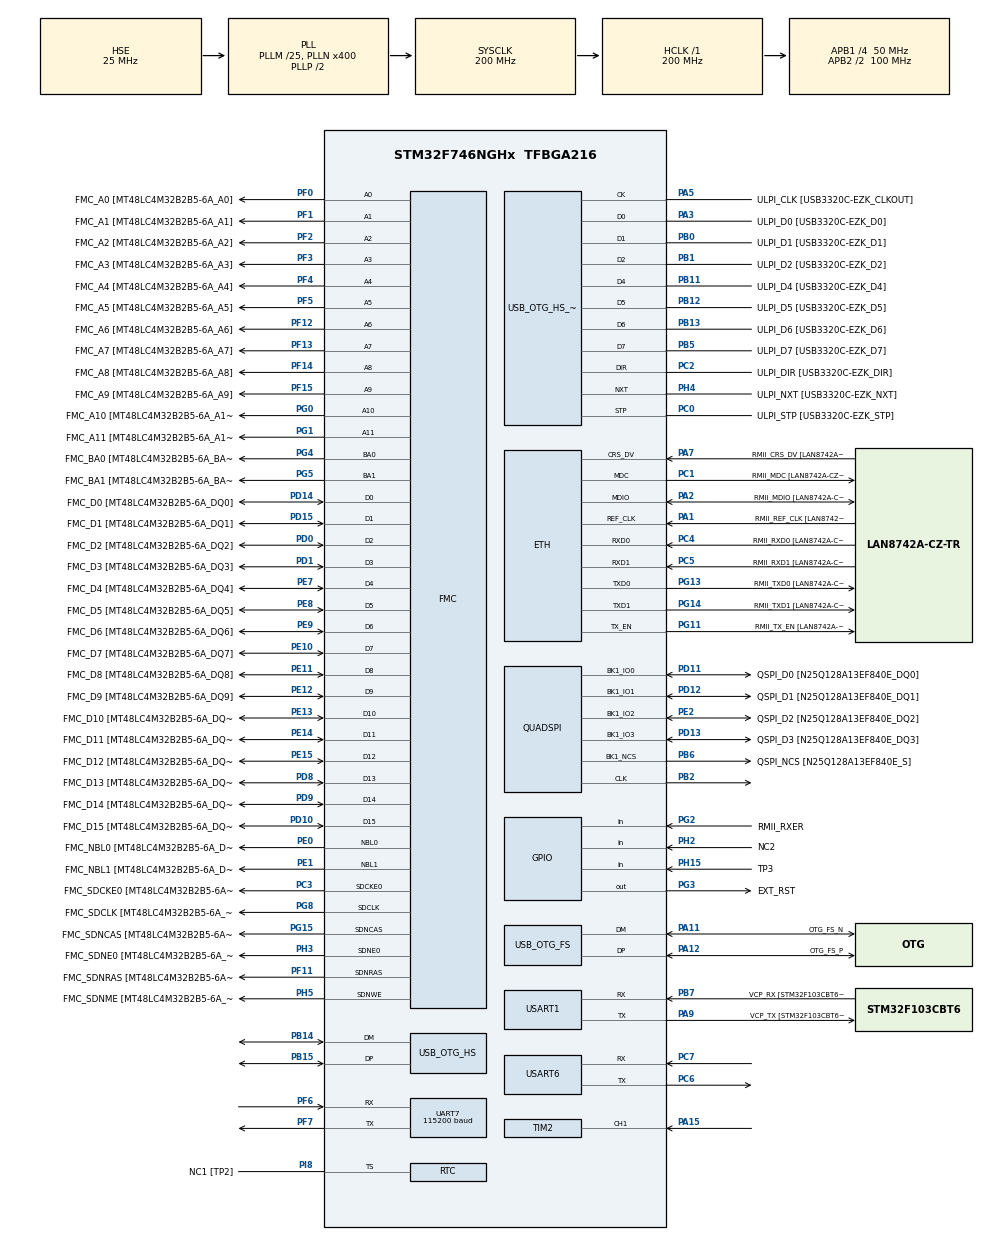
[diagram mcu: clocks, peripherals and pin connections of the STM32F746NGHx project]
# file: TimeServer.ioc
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CORTEX_M7.CPU_DCache=Disabled
CORTEX_M7.CPU_ICache=Disabled
CORTEX_M7.PREFETCH_ENABLE=0
Dma.Request0=USART6_TX
Dma.Request1=UART7_TX
Dma.Request2=USART1_RX
Dma.Request3=USART1_TX
Dma.Request4=USART6_RX
Dma.Request5=UART7_RX
Dma.UART7_RX.5.Direction=DMA_PERIPH_TO_MEMORY
Dma.UART7_RX.5.FIFOMode=DMA_FIFOMODE_ENABLE
Dma.UART7_RX.5.FIFOThreshold=DMA_FIFO_THRESHOLD_FULL
Dma.UART7_RX.5.Instance=DMA1_Stream3
Dma.UART7_RX.5.MemBurst=DMA_MBURST_SINGLE
Dma.UART7_RX.5.MemDataAlignment=DMA_MDATAALIGN_BYTE
Dma.UART7_RX.5.MemInc=DMA_MINC_ENABLE
Dma.UART7_RX.5.Mode=DMA_NORMAL
Dma.UART7_RX.5.PeriphBurst=DMA_PBURST_SINGLE
Dma.UART7_RX.5.PeriphDataAlignment=DMA_PDATAALIGN_BYTE
Dma.UART7_RX.5.PeriphInc=DMA_PINC_DISABLE
Dma.UART7_RX.5.Priority=DMA_PRIORITY_LOW
Dma.UART7_TX.1.Direction=DMA_MEMORY_TO_PERIPH
Dma.UART7_TX.1.FIFOMode=DMA_FIFOMODE_ENABLE
Dma.UART7_TX.1.FIFOThreshold=DMA_FIFO_THRESHOLD_FULL
Dma.UART7_TX.1.Instance=DMA1_Stream1
Dma.UART7_TX.1.MemBurst=DMA_MBURST_SINGLE
Dma.UART7_TX.1.MemDataAlignment=DMA_MDATAALIGN_BYTE
Dma.UART7_TX.1.MemInc=DMA_MINC_ENABLE
Dma.UART7_TX.1.Mode=DMA_NORMAL
Dma.UART7_TX.1.PeriphBurst=DMA_PBURST_SINGLE
Dma.UART7_TX.1.PeriphDataAlignment=DMA_PDATAALIGN_BYTE
Dma.UART7_TX.1.PeriphInc=DMA_PINC_DISABLE
Dma.UART7_TX.1.Priority=DMA_PRIORITY_LOW
Dma.USART1_RX.2.Direction=DMA_PERIPH_TO_MEMORY
Dma.USART1_RX.2.FIFOMode=DMA_FIFOMODE_DISABLE
Dma.USART1_RX.2.Instance=DMA2_Stream2
Dma.USART1_RX.2.MemDataAlignment=DMA_MDATAALIGN_BYTE
Dma.USART1_RX.2.MemInc=DMA_MINC_ENABLE
Dma.USART1_RX.2.Mode=DMA_NORMAL
Dma.USART1_RX.2.PeriphDataAlignment=DMA_PDATAALIGN_BYTE
Dma.USART1_RX.2.PeriphInc=DMA_PINC_DISABLE
Dma.USART1_RX.2.Priority=DMA_PRIORITY_LOW
Dma.USART1_TX.3.Direction=DMA_MEMORY_TO_PERIPH
Dma.USART1_TX.3.FIFOMode=DMA_FIFOMODE_DISABLE
Dma.USART1_TX.3.Instance=DMA2_Stream7
Dma.USART1_TX.3.MemDataAlignment=DMA_MDATAALIGN_BYTE
Dma.USART1_TX.3.MemInc=DMA_MINC_ENABLE
Dma.USART1_TX.3.Mode=DMA_NORMAL
Dma.USART1_TX.3.PeriphDataAlignment=DMA_PDATAALIGN_BYTE
Dma.USART1_TX.3.PeriphInc=DMA_PINC_DISABLE
Dma.USART1_TX.3.Priority=DMA_PRIORITY_LOW
Dma.USART6_RX.4.Direction=DMA_PERIPH_TO_MEMORY
Dma.USART6_RX.4.FIFOMode=DMA_FIFOMODE_ENABLE
Dma.USART6_RX.4.FIFOThreshold=DMA_FIFO_THRESHOLD_FULL
Dma.USART6_RX.4.Instance=DMA2_Stream1
Dma.USART6_RX.4.MemBurst=DMA_MBURST_SINGLE
Dma.USART6_RX.4.MemDataAlignment=DMA_MDATAALIGN_BYTE
Dma.USART6_RX.4.MemInc=DMA_MINC_ENABLE
Dma.USART6_RX.4.Mode=DMA_NORMAL
Dma.USART6_RX.4.PeriphBurst=DMA_PBURST_SINGLE
Dma.USART6_RX.4.PeriphDataAlignment=DMA_PDATAALIGN_BYTE
Dma.USART6_RX.4.PeriphInc=DMA_PINC_DISABLE
Dma.USART6_RX.4.Priority=DMA_PRIORITY_LOW
Dma.USART6_TX.0.Direction=DMA_MEMORY_TO_PERIPH
Dma.USART6_TX.0.FIFOMode=DMA_FIFOMODE_DISABLE
Dma.USART6_TX.0.Instance=DMA2_Stream6
Dma.USART6_TX.0.MemDataAlignment=DMA_MDATAALIGN_BYTE
Dma.USART6_TX.0.MemInc=DMA_MINC_ENABLE
Dma.USART6_TX.0.Mode=DMA_NORMAL
Dma.USART6_TX.0.PeriphDataAlignment=DMA_PDATAALIGN_BYTE
Dma.USART6_TX.0.PeriphInc=DMA_PINC_DISABLE
Dma.USART6_TX.0.Priority=DMA_PRIORITY_LOW
ETH.MediaInterface=ETH_MEDIA_INTERFACE_RMII
ETH.PHY_CONFIG_DELAY=0xfff
ETH.PHY_Name=LAN8742A_PHY_ADDRESS
ETH.PHY_RESET_DELAY=0x00000FFF
ETH.PhyAddress=0
FMC.CASLatency1=FMC_SDRAM_CAS_LATENCY_3
FMC.ExitSelfRefreshDelay1=7
FMC.LoadToActiveDelay1=2
FMC.RCDDelay1=2
FMC.RPDelay1=2
FMC.RPDelay2=2
FMC.ReadBurst1=FMC_SDRAM_RBURST_ENABLE
FMC.ReadBurst2=FMC_SDRAM_RBURST_ENABLE
FMC.RowCycleDelay1=7
FMC.RowCycleDelay2=7
FMC.SDClockPeriod1=FMC_SDRAM_CLOCK_PERIOD_2
FMC.SDClockPeriod2=FMC_SDRAM_CLOCK_PERIOD_2
FMC.SelfRefreshTime1=4
FMC.WriteRecoveryTime1=3
FREERTOS.Tasks01=defaultTask,24,4096,StartDefaultTask,Default,NULL,Dynamic,NULL,NULL
FREERTOS.configCHECK_FOR_STACK_OVERFLOW=2
FREERTOS.configENABLE_FPU=1
FREERTOS.configTOTAL_HEAP_SIZE=32768
FREERTOS.configUSE_APPLICATION_TASK_TAG=1
FREERTOS.configUSE_COUNTING_SEMAPHORES=1
FREERTOS.configUSE_IDLE_HOOK=0
FREERTOS.configUSE_MALLOC_FAILED_HOOK=1
FREERTOS.configUSE_POSIX_ERRNO=1
FREERTOS.configUSE_RECURSIVE_MUTEXES=1
Mcu.Family=STM32F7
Mcu.Name=STM32F746NGHx
Mcu.Package=TFBGA216
NVIC.DMA1_Stream1_IRQn=true\:5\:0\:false\:false\:true\:true\:false\:true
NVIC.DMA1_Stream3_IRQn=true\:5\:0\:false\:false\:true\:true\:false\:true
NVIC.DMA2_Stream1_IRQn=true\:5\:0\:false\:false\:true\:true\:false\:true
NVIC.DMA2_Stream2_IRQn=true\:5\:0\:false\:false\:true\:true\:false\:true
NVIC.DMA2_Stream6_IRQn=true\:5\:0\:false\:false\:true\:true\:false\:true
NVIC.DMA2_Stream7_IRQn=true\:5\:0\:false\:false\:true\:true\:false\:true
NVIC.OTG_FS_IRQn=true\:5\:0\:false\:false\:true\:true\:true\:true
NVIC.OTG_HS_IRQn=true\:5\:0\:false\:false\:true\:true\:false\:true
NVIC.PriorityGroup=NVIC_PRIORITYGROUP_4
NVIC.TIM6_DAC_IRQn=true\:0\:0\:false\:false\:true\:false\:false\:true
NVIC.TimeBase=TIM6_DAC_IRQn
NVIC.TimeBaseIP=TIM6
NVIC.UART7_IRQn=true\:5\:0\:false\:false\:true\:true\:true\:true
NVIC.USART1_IRQn=true\:5\:0\:false\:false\:true\:true\:true\:true
NVIC.USART6_IRQn=true\:5\:0\:false\:false\:true\:true\:true\:true
PA1.GPIO_Label=RMII_REF_CLK [LAN8742A-CZ-TR_REFCLK0]
PA1.Mode=RMII
PA1.Signal=ETH_REF_CLK
PA11.GPIO_Label=OTG_FS_N
PA11.Mode=Device_Only
PA11.Signal=USB_OTG_FS_DM
PA12.GPIO_Label=OTG_FS_P
PA12.Mode=Device_Only
PA12.Signal=USB_OTG_FS_DP
PA13.GPIO_Label=SWDIO
PA13.Mode=Serial_Wire
PA13.Signal=SYS_JTMS-SWDIO
PA14.GPIO_Label=SWCLK
PA14.Mode=Serial_Wire
PA14.Signal=SYS_JTCK-SWCLK
PA15.Signal=S_TIM2_CH1_ETR
PA2.GPIO_Label=RMII_MDIO [LAN8742A-CZ-TR_MDIO]
PA2.Mode=RMII
PA2.Signal=ETH_MDIO
PA3.GPIO_Label=ULPI_D0 [USB3320C-EZK_D0]
PA3.Mode=Host_HS
PA3.Signal=USB_OTG_HS_ULPI_D0
PA5.GPIO_Label=ULPI_CLK [USB3320C-EZK_CLKOUT]
PA5.Mode=Host_HS
PA5.Signal=USB_OTG_HS_ULPI_CK
PA7.GPIO_Label=RMII_CRS_DV [LAN8742A-CZ-TR_CRS_DV]
PA7.Mode=RMII
PA7.Signal=ETH_CRS_DV
PA9.GPIO_Label=VCP_TX [STM32F103CBT6_PA3]
PA9.GPIO_Mode=GPIO_MODE_AF_PP
PA9.GPIO_PuPd=GPIO_NOPULL
PA9.GPIO_Speed=GPIO_SPEED_FREQ_LOW
PA9.Mode=Asynchronous
PA9.Signal=USART1_TX
PB0.GPIO_Label=ULPI_D1 [USB3320C-EZK_D1]
PB0.Mode=Host_HS
PB0.Signal=USB_OTG_HS_ULPI_D1
PB1.GPIO_Label=ULPI_D2 [USB3320C-EZK_D2]
PB1.Mode=Host_HS
PB1.Signal=USB_OTG_HS_ULPI_D2
PB11.GPIO_Label=ULPI_D4 [USB3320C-EZK_D4]
PB11.Mode=Host_HS
PB11.Signal=USB_OTG_HS_ULPI_D4
PB12.GPIO_Label=ULPI_D5 [USB3320C-EZK_D5]
PB12.Mode=Host_HS
PB12.Signal=USB_OTG_HS_ULPI_D5
PB13.GPIO_Label=ULPI_D6 [USB3320C-EZK_D6]
PB13.Mode=Host_HS
PB13.Signal=USB_OTG_HS_ULPI_D6
PB14.Mode=Device_Only_FS
PB14.Signal=USB_OTG_HS_DM
PB15.Mode=Device_Only_FS
PB15.Signal=USB_OTG_HS_DP
PB2.Mode=Single Bank 1
PB2.Signal=QUADSPI_CLK
PB5.GPIO_Label=ULPI_D7 [USB3320C-EZK_D7]
PB5.Mode=Host_HS
PB5.Signal=USB_OTG_HS_ULPI_D7
PB6.GPIO_Label=QSPI_NCS [N25Q128A13EF840E_S]
PB6.Mode=Single Bank 1
PB6.Signal=QUADSPI_BK1_NCS
PB7.GPIO_Label=VCP_RX [STM32F103CBT6_PA2]
PB7.GPIO_Mode=GPIO_MODE_AF_PP
PB7.GPIO_PuPd=GPIO_NOPULL
PB7.GPIO_Speed=GPIO_SPEED_FREQ_LOW
PB7.Mode=Asynchronous
PB7.Signal=USART1_RX
PC0.GPIO_Label=ULPI_STP [USB3320C-EZK_STP]
PC0.Mode=Host_HS
PC0.Signal=USB_OTG_HS_ULPI_STP
PC1.GPIO_Label=RMII_MDC [LAN8742A-CZ-TR_MDC]
PC1.Mode=RMII
PC1.Signal=ETH_MDC
PC10.GPIO_Label=SDMMC_D2
PC10.Signal=SDMMC1_D2
PC11.GPIO_Label=SDMMC_D3
PC11.Signal=SDMMC1_D3
PC12.GPIO_Label=SDMMC_CK
PC12.Signal=SDMMC1_CK
PC14/OSC32_IN.GPIO_Label=RCC_OSC32_IN
PC14/OSC32_IN.Mode=LSE-External-Oscillator
PC14/OSC32_IN.Signal=RCC_OSC32_IN
PC15/OSC32_OUT.GPIO_Label=RCC_OSC32_OUT
PC15/OSC32_OUT.Mode=LSE-External-Oscillator
PC15/OSC32_OUT.Signal=RCC_OSC32_OUT
PC2.GPIO_Label=ULPI_DIR [USB3320C-EZK_DIR]
PC2.Mode=Host_HS
PC2.Signal=USB_OTG_HS_ULPI_DIR
PC3.GPIO_Label=FMC_SDCKE0 [MT48LC4M32B2B5-6A_CKE]
PC3.Mode=SdramChipSelect1_1
PC3.Signal=FMC_SDCKE0
PC4.GPIO_Label=RMII_RXD0 [LAN8742A-CZ-TR_RXD0]
PC4.Mode=RMII
PC4.Signal=ETH_RXD0
PC5.GPIO_Label=RMII_RXD1 [LAN8742A-CZ-TR_RXD1]
PC5.Mode=RMII
PC5.Signal=ETH_RXD1
PC6.Mode=Asynchronous
PC6.Signal=USART6_TX
PC7.Mode=Asynchronous
PC7.Signal=USART6_RX
PC8.Signal=SDMMC1_D0
PC9.Signal=SDMMC1_D1
PD0.GPIO_Label=FMC_D2 [MT48LC4M32B2B5-6A_DQ2]
PD0.Signal=FMC_D2_DA2
PD1.GPIO_Label=FMC_D3 [MT48LC4M32B2B5-6A_DQ3]
PD1.Signal=FMC_D3_DA3
PD10.GPIO_Label=FMC_D15 [MT48LC4M32B2B5-6A_DQ15]
PD10.Signal=FMC_D15_DA15
PD11.GPIO_Label=QSPI_D0 [N25Q128A13EF840E_DQ0]
PD11.Mode=Single Bank 1
PD11.Signal=QUADSPI_BK1_IO0
PD12.GPIO_Label=QSPI_D1 [N25Q128A13EF840E_DQ1]
PD12.Mode=Single Bank 1
PD12.Signal=QUADSPI_BK1_IO1
PD13.GPIO_Label=QSPI_D3 [N25Q128A13EF840E_DQ3]
PD13.Mode=Single Bank 1
PD13.Signal=QUADSPI_BK1_IO3
PD14.GPIO_Label=FMC_D0 [MT48LC4M32B2B5-6A_DQ0]
PD14.Signal=FMC_D0_DA0
PD15.GPIO_Label=FMC_D1 [MT48LC4M32B2B5-6A_DQ1]
PD15.Signal=FMC_D1_DA1
PD2.GPIO_Label=SDMMC_CMD
PD2.Signal=SDMMC1_CMD
PD8.GPIO_Label=FMC_D13 [MT48LC4M32B2B5-6A_DQ13]
PD8.Signal=FMC_D13_DA13
PD9.GPIO_Label=FMC_D14 [MT48LC4M32B2B5-6A_DQ14]
PD9.Signal=FMC_D14_DA14
PE0.GPIO_Label=FMC_NBL0 [MT48LC4M32B2B5-6A_DQM0]
PE0.Signal=FMC_NBL0
PE1.GPIO_Label=FMC_NBL1 [MT48LC4M32B2B5-6A_DQM1]
PE1.Signal=FMC_NBL1
PE10.GPIO_Label=FMC_D7 [MT48LC4M32B2B5-6A_DQ7]
PE10.Signal=FMC_D7_DA7
PE11.GPIO_Label=FMC_D8 [MT48LC4M32B2B5-6A_DQ8]
PE11.Signal=FMC_D8_DA8
PE12.GPIO_Label=FMC_D9 [MT48LC4M32B2B5-6A_DQ9]
PE12.Signal=FMC_D9_DA9
PE13.GPIO_Label=FMC_D10 [MT48LC4M32B2B5-6A_DQ10]
PE13.Signal=FMC_D10_DA10
PE14.GPIO_Label=FMC_D11 [MT48LC4M32B2B5-6A_DQ11]
PE14.Signal=FMC_D11_DA11
PE15.GPIO_Label=FMC_D12 [MT48LC4M32B2B5-6A_DQ12]
PE15.Signal=FMC_D12_DA12
PE2.GPIO_Label=QSPI_D2 [N25Q128A13EF840E_DQ2]
PE2.Mode=Single Bank 1
PE2.Signal=QUADSPI_BK1_IO2
PE7.GPIO_Label=FMC_D4 [MT48LC4M32B2B5-6A_DQ4]
PE7.Signal=FMC_D4_DA4
PE8.GPIO_Label=FMC_D5 [MT48LC4M32B2B5-6A_DQ5]
PE8.Signal=FMC_D5_DA5
PE9.GPIO_Label=FMC_D6 [MT48LC4M32B2B5-6A_DQ6]
PE9.Signal=FMC_D6_DA6
PF0.GPIO_Label=FMC_A0 [MT48LC4M32B2B5-6A_A0]
PF0.Signal=FMC_A0
PF1.GPIO_Label=FMC_A1 [MT48LC4M32B2B5-6A_A1]
PF1.Signal=FMC_A1
PF11.GPIO_Label=FMC_SDNRAS [MT48LC4M32B2B5-6A_RAS]
PF11.Signal=FMC_SDNRAS
PF12.GPIO_Label=FMC_A6 [MT48LC4M32B2B5-6A_A6]
PF12.Signal=FMC_A6
PF13.GPIO_Label=FMC_A7 [MT48LC4M32B2B5-6A_A7]
PF13.Signal=FMC_A7
PF14.GPIO_Label=FMC_A8 [MT48LC4M32B2B5-6A_A8]
PF14.Signal=FMC_A8
PF15.GPIO_Label=FMC_A9 [MT48LC4M32B2B5-6A_A9]
PF15.Signal=FMC_A9
PF2.GPIO_Label=FMC_A2 [MT48LC4M32B2B5-6A_A2]
PF2.Signal=FMC_A2
PF3.GPIO_Label=FMC_A3 [MT48LC4M32B2B5-6A_A3]
PF3.Signal=FMC_A3
PF4.GPIO_Label=FMC_A4 [MT48LC4M32B2B5-6A_A4]
PF4.Signal=FMC_A4
PF5.GPIO_Label=FMC_A5 [MT48LC4M32B2B5-6A_A5]
PF5.Signal=FMC_A5
PF6.Mode=Asynchronous
PF6.Signal=UART7_RX
PF7.Mode=Asynchronous
PF7.Signal=UART7_TX
PG0.GPIO_Label=FMC_A10 [MT48LC4M32B2B5-6A_A10]
PG0.Signal=FMC_A10
PG1.GPIO_Label=FMC_A11 [MT48LC4M32B2B5-6A_A11]
PG1.Signal=FMC_A11
PG11.GPIO_Label=RMII_TX_EN [LAN8742A-CZ-TR_TXEN]
PG11.Mode=RMII
PG11.Signal=ETH_TX_EN
PG13.GPIO_Label=RMII_TXD0 [LAN8742A-CZ-TR_TXD0]
PG13.Mode=RMII
PG13.Signal=ETH_TXD0
PG14.GPIO_Label=RMII_TXD1 [LAN8742A-CZ-TR_TXD1]
PG14.Mode=RMII
PG14.Signal=ETH_TXD1
PG15.GPIO_Label=FMC_SDNCAS [MT48LC4M32B2B5-6A_CAS]
PG15.Signal=FMC_SDNCAS
PG2.GPIO_Label=RMII_RXER
PG2.Signal=GPIO_Input
PG3.GPIO_Label=EXT_RST
PG3.Signal=GPIO_Output
PG4.GPIO_Label=FMC_BA0 [MT48LC4M32B2B5-6A_BA0]
PG4.Signal=FMC_A14_BA0
PG5.GPIO_Label=FMC_BA1 [MT48LC4M32B2B5-6A_BA1]
PG5.Signal=FMC_A15_BA1
PG8.GPIO_Label=FMC_SDCLK [MT48LC4M32B2B5-6A_CLK]
PG8.Signal=FMC_SDCLK
PH0/OSC_IN.GPIO_Label=OSC_25M [NZ2520SB-25.00M_OUT]
PH0/OSC_IN.Mode=HSE-External-Oscillator
PH0/OSC_IN.Signal=RCC_OSC_IN
PH1/OSC_OUT.Mode=HSE-External-Oscillator
PH1/OSC_OUT.Signal=RCC_OSC_OUT
PH15.GPIO_Label=TP3
PH15.Signal=GPIO_Input
PH2.GPIO_Label=NC2
PH2.Signal=GPIO_Input
PH3.GPIO_Label=FMC_SDNE0 [MT48LC4M32B2B5-6A_CS]
PH3.Mode=SdramChipSelect1_1
PH3.Signal=FMC_SDNE0
PH4.GPIO_Label=ULPI_NXT [USB3320C-EZK_NXT]
PH4.Mode=Host_HS
PH4.Signal=USB_OTG_HS_ULPI_NXT
PH5.GPIO_Label=FMC_SDNME [MT48LC4M32B2B5-6A_WE]
PH5.Signal=FMC_SDNWE
PI8.GPIO_Label=NC1 [TP2]
PI8.Mode=Timestamp enabled - Input Enabled to TS
PI8.Signal=RTC_TS
ProjectManager.HeapSize=0x200
ProjectManager.StackSize=0x400
ProjectManager.TargetToolchain=SW4STM32
RCC.AHBFreq_Value=200000000
RCC.APB1CLKDivider=RCC_HCLK_DIV4
RCC.APB1Freq_Value=50000000
RCC.APB1TimFreq_Value=100000000
RCC.APB2CLKDivider=RCC_HCLK_DIV2
RCC.APB2Freq_Value=100000000
RCC.APB2TimFreq_Value=200000000
RCC.CortexFreq_Value=200000000
RCC.HCLKFreq_Value=200000000
RCC.HSE_VALUE=25000000
RCC.HSI_VALUE=16000000
RCC.PLL48CLockSelection=RCC_CLK48SOURCE_PLLSAIP
RCC.PLLI2SN=100
RCC.PLLM=25
RCC.PLLN=400
RCC.PLLQ=9
RCC.PLLSAIN=384
RCC.PLLSAIP=RCC_PLLSAIP_DIV8
RCC.PLLSAIR=5
RCC.PLLSAIRDiv=RCC_PLLSAIDIVR_8
RCC.SDMMCClockSelection=RCC_SDMMC1CLKSOURCE_CLK48
RCC.SYSCLKFreq_VALUE=200000000
RCC.SYSCLKSource=RCC_SYSCLKSOURCE_PLLCLK
RCC.USBFreq_Value=48000000
RCC.VCOOutputFreq_Value=400000000
RTC.Alarm-Alarm\ A=RTC_ALARM_A
RTC.Alarm_B-Alarm\ B=RTC_ALARM_B
SH.FMC_A0.0=FMC_A0,12b-sda1
SH.FMC_A1.0=FMC_A1,12b-sda1
SH.FMC_A10.0=FMC_A10,12b-sda1
SH.FMC_A11.0=FMC_A11,12b-sda1
SH.FMC_A14_BA0.0=FMC_BA0,FourSdramBanks1
SH.FMC_A15_BA1.0=FMC_BA1,FourSdramBanks1
SH.FMC_A2.0=FMC_A2,12b-sda1
SH.FMC_A3.0=FMC_A3,12b-sda1
SH.FMC_A4.0=FMC_A4,12b-sda1
SH.FMC_A5.0=FMC_A5,12b-sda1
SH.FMC_A6.0=FMC_A6,12b-sda1
SH.FMC_A7.0=FMC_A7,12b-sda1
SH.FMC_A8.0=FMC_A8,12b-sda1
SH.FMC_A9.0=FMC_A9,12b-sda1
SH.FMC_D0_DA0.0=FMC_D0,sd-16b-d1
SH.FMC_D10_DA10.0=FMC_D10,sd-16b-d1
SH.FMC_D11_DA11.0=FMC_D11,sd-16b-d1
SH.FMC_D12_DA12.0=FMC_D12,sd-16b-d1
SH.FMC_D13_DA13.0=FMC_D13,sd-16b-d1
SH.FMC_D14_DA14.0=FMC_D14,sd-16b-d1
SH.FMC_D15_DA15.0=FMC_D15,sd-16b-d1
SH.FMC_D1_DA1.0=FMC_D1,sd-16b-d1
SH.FMC_D2_DA2.0=FMC_D2,sd-16b-d1
SH.FMC_D3_DA3.0=FMC_D3,sd-16b-d1
SH.FMC_D4_DA4.0=FMC_D4,sd-16b-d1
SH.FMC_D5_DA5.0=FMC_D5,sd-16b-d1
SH.FMC_D6_DA6.0=FMC_D6,sd-16b-d1
SH.FMC_D7_DA7.0=FMC_D7,sd-16b-d1
SH.FMC_D8_DA8.0=FMC_D8,sd-16b-d1
SH.FMC_D9_DA9.0=FMC_D9,sd-16b-d1
SH.FMC_NBL0.0=FMC_NBL0,Sd2ByteEnable1
SH.FMC_NBL1.0=FMC_NBL1,Sd2ByteEnable1
SH.FMC_SDCLK.0=FMC_SDCLK,12b-sda1
SH.FMC_SDNCAS.0=FMC_SDNCAS,12b-sda1
SH.FMC_SDNRAS.0=FMC_SDNRAS,12b-sda1
SH.FMC_SDNWE.0=FMC_SDNWE,12b-sda1
SH.S_TIM2_CH1_ETR.0=TIM2_CH1,Input_Capture1_from_TI1
TIM2.Channel-Input_Capture1_from_TI1=TIM_CHANNEL_1
UART7.BaudRate=115200
USART1.VirtualMode-Asynchronous=VM_ASYNC
USART6.VirtualMode-Asynchronous=VM_ASYNC
USB_DEVICE.CLASS_NAME_HS=CDC
USB_DEVICE.VirtualMode-CDC_HS=Cdc
USB_DEVICE.VirtualModeHS=Cdc_HS
USB_OTG_FS.VirtualMode=Device_Only
USB_OTG_HS.VirtualMode-Device_Only_FS=Device_Only_FS
VP_CRC_VS_CRC.Mode=CRC_Activate
VP_FREERTOS_VS_CMSIS_V2.Mode=CMSIS_V2
VP_RTC_VS_RTC_Activate.Mode=RTC_Enabled
VP_RTC_VS_RTC_Alarm_A_Intern.Mode=Alarm A
VP_RTC_VS_RTC_Alarm_B_Intern.Mode=Alarm B
VP_RTC_VS_RTC_Calendar.Mode=RTC_Calendar
VP_SYS_VS_tim6.Mode=TIM6
VP_TIM1_VS_ClockSourceINT.Mode=Internal
VP_TIM2_VS_ClockSourceINT.Mode=Internal
VP_USB_DEVICE_VS_USB_DEVICE_CDC_HS.Mode=CDC_HS
board=STM32F746G-DISCO

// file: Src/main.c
/* USER CODE BEGIN Header */
/**
  ******************************************************************************
  * @file           : main.c
  * @brief          : Main program body
  ******************************************************************************
  * @attention
  *
  * <h2><center>&copy; Copyright (c) 2020 STMicroelectronics.
  * All rights reserved.</center></h2>
  *
  * This software component is licensed by ST under Ultimate Liberty license
  * SLA0044, the "License"; You may not use this file except in compliance with
  * the License. You may obtain a copy of the License at:
  *                             www.st.com/SLA0044
  *
  ******************************************************************************
  */
/* USER CODE END Header */

#include "main.h"
#include "cmsis_os.h"
#include "usb_device.h"

/* USER CODE BEGIN Includes */
#include <stdio.h>
/* USER CODE END Includes */

CRC_HandleTypeDef hcrc;

ETH_HandleTypeDef heth;

QSPI_HandleTypeDef hqspi;

RTC_HandleTypeDef hrtc;

TIM_HandleTypeDef htim1;
TIM_HandleTypeDef htim2;

UART_HandleTypeDef huart7;
UART_HandleTypeDef huart1;
UART_HandleTypeDef huart6;
DMA_HandleTypeDef hdma_uart7_tx;
DMA_HandleTypeDef hdma_uart7_rx;
DMA_HandleTypeDef hdma_usart1_rx;
DMA_HandleTypeDef hdma_usart1_tx;
DMA_HandleTypeDef hdma_usart6_tx;
DMA_HandleTypeDef hdma_usart6_rx;

PCD_HandleTypeDef hpcd_USB_OTG_FS;

SDRAM_HandleTypeDef hsdram1;

/* Definitions for defaultTask */
osThreadId_t defaultTaskHandle;
const osThreadAttr_t defaultTask_attributes = {
  .name = "defaultTask",
  .priority = (osPriority_t) osPriorityNormal,
  .stack_size = 4096 * 4
};
/* USER CODE BEGIN PV */
struct CircBuf pcNmeaRx_cBuf;
struct CircBuf gpsNmeaRx_cBuf;
#if(0)
struct CircBuf pcBinrRx_cBuf;
struct CircBuf gpsBinrRx_cBuf;
#endif
UART_HandleTypeDef * pcNmeaUart = &huart7;
UART_HandleTypeDef * gpsNmeaUart = &huart6;
UART_HandleTypeDef * debugUart	= &huart1;
#if(0)
UART_HandleTypeDef * pcBinrUart;
UART_HandleTypeDef * gpsBinrUart;
#endif

/* Flags */
bool pcNmeaUart_isSending = false;
bool gpsNmeaUart_isSending = false;
bool debugUart_isSending = false;

osSemaphoreId_t gpsNmeaRx_semaHandle;
osSemaphoreId_t pcNmeaRx_semaHandle;
#if(0)
osSemaphoreId_t gpsBinrRx_semaHandle;
osSemaphoreId_t pcBinrRx_semaHandle;
#endif

struct Node * gpsNmeaMsgList;
struct Node * pcNmeaMsgList;

/* USER CODE END PV */

void SystemClock_Config(void);
static void MX_GPIO_Init(void);
static void MX_DMA_Init(void);
static void MX_CRC_Init(void);
static void MX_ETH_Init(void);
static void MX_FMC_Init(void);
static void MX_QUADSPI_Init(void);
static void MX_RTC_Init(void);
static void MX_TIM1_Init(void);
static void MX_TIM2_Init(void);
static void MX_UART7_Init(void);
static void MX_USART1_UART_Init(void);
static void MX_USART6_UART_Init(void);
static void MX_USB_OTG_FS_PCD_Init(void);
void StartDefaultTask(void *argument);

/* USER CODE BEGIN PFP */
osThreadId_t pcNmeaRx_thrdHandle;
osThreadId_t gpsNmeaRx_thrdHandle;
void pcNmeaRx_thread(void * argument);
void gpsNmeaRx_thread(void * argument);

/* USER CODE END PFP */

int main(void)
{

  /* MCU Configuration--------------------------------------------------------*/

  /* Reset of all peripherals, Initializes the Flash interface and the Systick. */
  HAL_Init();

  /* Configure the system clock */
  SystemClock_Config();

  /* Initialize all configured peripherals */
  MX_GPIO_Init();
  MX_DMA_Init();
  MX_CRC_Init();
  MX_ETH_Init();
  MX_FMC_Init();
  MX_QUADSPI_Init();
  MX_RTC_Init();
  MX_TIM1_Init();
  MX_TIM2_Init();
  MX_UART7_Init();
  MX_USART1_UART_Init();
  MX_USART6_UART_Init();
  MX_USB_OTG_FS_PCD_Init();

  /* Init scheduler */
  osKernelInitialize();

  /* USER CODE BEGIN RTOS_MUTEX */

	/* Heap model initialized above.
	* So I assume it is safe to ask for heap memory here. */
  	int bufNum = 0;
	gpsNmeaMsgList = initList(NMEA_MSG_MAX_SIZE);
	if(!gpsNmeaMsgList) return EXIT_FAILURE;
	for(bufNum = 1 /*exclude head node*/; \
		bufNum < NMEA_MSG_LIST_LEN; bufNum++)
	{
		addNode(gpsNmeaMsgList);
	}
	pcNmeaMsgList = initList(NMEA_MSG_MAX_SIZE);
	if(!pcNmeaMsgList) return EXIT_FAILURE;
	for(bufNum = 1 /*exclude head node*/; \
		bufNum < NMEA_MSG_LIST_LEN; bufNum++)
	{
		addNode(pcNmeaMsgList);
	}

  /* add mutexes, ... */
  /* USER CODE END RTOS_MUTEX */

  /* USER CODE BEGIN RTOS_SEMAPHORES */
  /* add semaphores, ... */
  gpsNmeaRx_semaHandle = osSemaphoreNew(1, 0, NULL);
  pcNmeaRx_semaHandle = osSemaphoreNew(1, 0, NULL);

  /* USER CODE END RTOS_SEMAPHORES */

  /* Create the thread(s) */
  /* creation of defaultTask */
  defaultTaskHandle = osThreadNew(StartDefaultTask, NULL, &defaultTask_attributes);

  /* USER CODE BEGIN RTOS_THREADS */
  /* add threads, ... */
//  pcNmeaRx_thrdHandle = osThreadNew(pcNmeaRx_thread, NULL, NULL);
  gpsNmeaRx_thrdHandle = osThreadNew(gpsNmeaRx_thread, NULL, NULL);

  //extern const osThreadAttr_t pcNMEAmsgExtrr_thrdAtts;
  //pcNMEAmsgExtrr_thrdHandle = osThreadNew(pcNMEAmsgExtrr, NULL, &pcNMEAmsgExtrr_thrdAtts);
  /* USER CODE END RTOS_THREADS */

  /* Start scheduler */
  osKernelStart();

  /* We should never get here as control is now taken by the scheduler */
  /* Infinite loop */
  while (1)
  {

  }
}

void SystemClock_Config(void)
{
  RCC_OscInitTypeDef RCC_OscInitStruct = {0};
  RCC_ClkInitTypeDef RCC_ClkInitStruct = {0};
  RCC_PeriphCLKInitTypeDef PeriphClkInitStruct = {0};

  /** Configure LSE Drive Capability
  */
  HAL_PWR_EnableBkUpAccess();
  /** Configure the main internal regulator output voltage
  */
  __HAL_RCC_PWR_CLK_ENABLE();
  __HAL_PWR_VOLTAGESCALING_CONFIG(PWR_REGULATOR_VOLTAGE_SCALE1);
  /** Initializes the CPU, AHB and APB busses clocks
  */
  RCC_OscInitStruct.OscillatorType = RCC_OSCILLATORTYPE_LSI|RCC_OSCILLATORTYPE_HSE;
  RCC_OscInitStruct.HSEState = RCC_HSE_ON;
  RCC_OscInitStruct.LSIState = RCC_LSI_ON;
  RCC_OscInitStruct.PLL.PLLState = RCC_PLL_ON;
  RCC_OscInitStruct.PLL.PLLSource = RCC_PLLSOURCE_HSE;
  RCC_OscInitStruct.PLL.PLLM = 25;
  RCC_OscInitStruct.PLL.PLLN = 400;
  RCC_OscInitStruct.PLL.PLLP = RCC_PLLP_DIV2;
  RCC_OscInitStruct.PLL.PLLQ = 9;
  if (HAL_RCC_OscConfig(&RCC_OscInitStruct) != HAL_OK)
  {
    Error_Handler();
  }
  /** Activate the Over-Drive mode
  */
  if (HAL_PWREx_EnableOverDrive() != HAL_OK)
  {
    Error_Handler();
  }
  /** Initializes the CPU, AHB and APB busses clocks
  */
  RCC_ClkInitStruct.ClockType = RCC_CLOCKTYPE_HCLK|RCC_CLOCKTYPE_SYSCLK
                              |RCC_CLOCKTYPE_PCLK1|RCC_CLOCKTYPE_PCLK2;
  RCC_ClkInitStruct.SYSCLKSource = RCC_SYSCLKSOURCE_PLLCLK;
  RCC_ClkInitStruct.AHBCLKDivider = RCC_SYSCLK_DIV1;
  RCC_ClkInitStruct.APB1CLKDivider = RCC_HCLK_DIV4;
  RCC_ClkInitStruct.APB2CLKDivider = RCC_HCLK_DIV2;

  if (HAL_RCC_ClockConfig(&RCC_ClkInitStruct, FLASH_LATENCY_6) != HAL_OK)
  {
    Error_Handler();
  }
  PeriphClkInitStruct.PeriphClockSelection = RCC_PERIPHCLK_RTC|RCC_PERIPHCLK_USART1
                              |RCC_PERIPHCLK_USART6|RCC_PERIPHCLK_UART7
                              |RCC_PERIPHCLK_CLK48;
  PeriphClkInitStruct.PLLSAI.PLLSAIN = 384;
  PeriphClkInitStruct.PLLSAI.PLLSAIR = 5;
  PeriphClkInitStruct.PLLSAI.PLLSAIQ = 2;
  PeriphClkInitStruct.PLLSAI.PLLSAIP = RCC_PLLSAIP_DIV8;
  PeriphClkInitStruct.PLLSAIDivQ = 1;
  PeriphClkInitStruct.PLLSAIDivR = RCC_PLLSAIDIVR_8;
  PeriphClkInitStruct.RTCClockSelection = RCC_RTCCLKSOURCE_LSI;
  PeriphClkInitStruct.Usart1ClockSelection = RCC_USART1CLKSOURCE_PCLK2;
  PeriphClkInitStruct.Usart6ClockSelection = RCC_USART6CLKSOURCE_PCLK2;
  PeriphClkInitStruct.Uart7ClockSelection = RCC_UART7CLKSOURCE_PCLK1;
  PeriphClkInitStruct.Clk48ClockSelection = RCC_CLK48SOURCE_PLLSAIP;
  if (HAL_RCCEx_PeriphCLKConfig(&PeriphClkInitStruct) != HAL_OK)
  {
    Error_Handler();
  }
}

static void MX_CRC_Init(void)
{

  hcrc.Instance = CRC;
  hcrc.Init.DefaultPolynomialUse = DEFAULT_POLYNOMIAL_ENABLE;
  hcrc.Init.DefaultInitValueUse = DEFAULT_INIT_VALUE_ENABLE;
  hcrc.Init.InputDataInversionMode = CRC_INPUTDATA_INVERSION_NONE;
  hcrc.Init.OutputDataInversionMode = CRC_OUTPUTDATA_INVERSION_DISABLE;
  hcrc.InputDataFormat = CRC_INPUTDATA_FORMAT_BYTES;
  if (HAL_CRC_Init(&hcrc) != HAL_OK)
  {
    Error_Handler();
  }

}

static void MX_ETH_Init(void)
{

  heth.Instance = ETH;
  heth.Init.AutoNegotiation = ETH_AUTONEGOTIATION_ENABLE;
  heth.Init.PhyAddress = LAN8742A_PHY_ADDRESS;
  heth.Init.MACAddr[0] =   0x00;
  heth.Init.MACAddr[1] =   0x80;
  heth.Init.MACAddr[2] =   0xE1;
  heth.Init.MACAddr[3] =   0x00;
  heth.Init.MACAddr[4] =   0x00;
  heth.Init.MACAddr[5] =   0x00;
  heth.Init.RxMode = ETH_RXPOLLING_MODE;
  heth.Init.ChecksumMode = ETH_CHECKSUM_BY_HARDWARE;
  heth.Init.MediaInterface = ETH_MEDIA_INTERFACE_RMII;

  if (HAL_ETH_Init(&heth) != HAL_OK)
  {
    Error_Handler();
  }

}

static void MX_QUADSPI_Init(void)
{

  /* QUADSPI parameter configuration*/
  hqspi.Instance = QUADSPI;
  hqspi.Init.ClockPrescaler = 255;
  hqspi.Init.FifoThreshold = 1;
  hqspi.Init.SampleShifting = QSPI_SAMPLE_SHIFTING_NONE;
  hqspi.Init.FlashSize = 1;
  hqspi.Init.ChipSelectHighTime = QSPI_CS_HIGH_TIME_1_CYCLE;
  hqspi.Init.ClockMode = QSPI_CLOCK_MODE_0;
  hqspi.Init.FlashID = QSPI_FLASH_ID_1;
  hqspi.Init.DualFlash = QSPI_DUALFLASH_DISABLE;
  if (HAL_QSPI_Init(&hqspi) != HAL_OK)
  {
    Error_Handler();
  }

}

static void MX_RTC_Init(void)
{

  RTC_TimeTypeDef sTime = {0};
  RTC_DateTypeDef sDate = {0};
  RTC_AlarmTypeDef sAlarm = {0};

  /** Initialize RTC Only
  */
  hrtc.Instance = RTC;
  hrtc.Init.HourFormat = RTC_HOURFORMAT_24;
  hrtc.Init.AsynchPrediv = 127;
  hrtc.Init.SynchPrediv = 255;
  hrtc.Init.OutPut = RTC_OUTPUT_DISABLE;
  hrtc.Init.OutPutPolarity = RTC_OUTPUT_POLARITY_HIGH;
  hrtc.Init.OutPutType = RTC_OUTPUT_TYPE_OPENDRAIN;
  if (HAL_RTC_Init(&hrtc) != HAL_OK)
  {
    Error_Handler();
  }

  /** Initialize RTC and set the Time and Date
  */
  sTime.Hours = 0x0;
  sTime.Minutes = 0x0;
  sTime.Seconds = 0x0;
  sTime.DayLightSaving = RTC_DAYLIGHTSAVING_NONE;
  sTime.StoreOperation = RTC_STOREOPERATION_RESET;
  if (HAL_RTC_SetTime(&hrtc, &sTime, RTC_FORMAT_BCD) != HAL_OK)
  {
    Error_Handler();
  }
  sDate.WeekDay = RTC_WEEKDAY_MONDAY;
  sDate.Month = RTC_MONTH_JANUARY;
  sDate.Date = 0x1;
  sDate.Year = 0x0;
  if (HAL_RTC_SetDate(&hrtc, &sDate, RTC_FORMAT_BCD) != HAL_OK)
  {
    Error_Handler();
  }
  /** Enable the Alarm A
  */
  sAlarm.AlarmTime.Hours = 0x0;
  sAlarm.AlarmTime.Minutes = 0x0;
  sAlarm.AlarmTime.Seconds = 0x0;
  sAlarm.AlarmTime.SubSeconds = 0x0;
  sAlarm.AlarmTime.DayLightSaving = RTC_DAYLIGHTSAVING_NONE;
  sAlarm.AlarmTime.StoreOperation = RTC_STOREOPERATION_RESET;
  sAlarm.AlarmMask = RTC_ALARMMASK_NONE;
  sAlarm.AlarmSubSecondMask = RTC_ALARMSUBSECONDMASK_ALL;
  sAlarm.AlarmDateWeekDaySel = RTC_ALARMDATEWEEKDAYSEL_DATE;
  sAlarm.AlarmDateWeekDay = 0x1;
  sAlarm.Alarm = RTC_ALARM_A;
  if (HAL_RTC_SetAlarm(&hrtc, &sAlarm, RTC_FORMAT_BCD) != HAL_OK)
  {
    Error_Handler();
  }
  /** Enable the Alarm B
  */
  sAlarm.AlarmDateWeekDay = 0x1;
  sAlarm.Alarm = RTC_ALARM_B;
  if (HAL_RTC_SetAlarm(&hrtc, &sAlarm, RTC_FORMAT_BCD) != HAL_OK)
  {
    Error_Handler();
  }
  /** Enable the TimeStamp
  */
  if (HAL_RTCEx_SetTimeStamp(&hrtc, RTC_TIMESTAMPEDGE_RISING, RTC_TIMESTAMPPIN_POS1) != HAL_OK)
  {
    Error_Handler();
  }

}

static void MX_TIM1_Init(void)
{

  TIM_ClockConfigTypeDef sClockSourceConfig = {0};
  TIM_MasterConfigTypeDef sMasterConfig = {0};

  htim1.Instance = TIM1;
  htim1.Init.Prescaler = 0;
  htim1.Init.CounterMode = TIM_COUNTERMODE_UP;
  htim1.Init.Period = 0;
  htim1.Init.ClockDivision = TIM_CLOCKDIVISION_DIV1;
  htim1.Init.RepetitionCounter = 0;
  htim1.Init.AutoReloadPreload = TIM_AUTORELOAD_PRELOAD_DISABLE;
  if (HAL_TIM_Base_Init(&htim1) != HAL_OK)
  {
    Error_Handler();
  }
  sClockSourceConfig.ClockSource = TIM_CLOCKSOURCE_INTERNAL;
  if (HAL_TIM_ConfigClockSource(&htim1, &sClockSourceConfig) != HAL_OK)
  {
    Error_Handler();
  }
  sMasterConfig.MasterOutputTrigger = TIM_TRGO_RESET;
  sMasterConfig.MasterOutputTrigger2 = TIM_TRGO2_RESET;
  sMasterConfig.MasterSlaveMode = TIM_MASTERSLAVEMODE_DISABLE;
  if (HAL_TIMEx_MasterConfigSynchronization(&htim1, &sMasterConfig) != HAL_OK)
  {
    Error_Handler();
  }

}

static void MX_TIM2_Init(void)
{

  TIM_ClockConfigTypeDef sClockSourceConfig = {0};
  TIM_MasterConfigTypeDef sMasterConfig = {0};
  TIM_IC_InitTypeDef sConfigIC = {0};

  htim2.Instance = TIM2;
  htim2.Init.Prescaler = 0;
  htim2.Init.CounterMode = TIM_COUNTERMODE_UP;
  htim2.Init.Period = 0;
  htim2.Init.ClockDivision = TIM_CLOCKDIVISION_DIV1;
  htim2.Init.AutoReloadPreload = TIM_AUTORELOAD_PRELOAD_DISABLE;
  if (HAL_TIM_Base_Init(&htim2) != HAL_OK)
  {
    Error_Handler();
  }
  sClockSourceConfig.ClockSource = TIM_CLOCKSOURCE_INTERNAL;
  if (HAL_TIM_ConfigClockSource(&htim2, &sClockSourceConfig) != HAL_OK)
  {
    Error_Handler();
  }
  if (HAL_TIM_IC_Init(&htim2) != HAL_OK)
  {
    Error_Handler();
  }
  sMasterConfig.MasterOutputTrigger = TIM_TRGO_RESET;
  sMasterConfig.MasterSlaveMode = TIM_MASTERSLAVEMODE_DISABLE;
  if (HAL_TIMEx_MasterConfigSynchronization(&htim2, &sMasterConfig) != HAL_OK)
  {
    Error_Handler();
  }
  sConfigIC.ICPolarity = TIM_INPUTCHANNELPOLARITY_RISING;
  sConfigIC.ICSelection = TIM_ICSELECTION_DIRECTTI;
  sConfigIC.ICPrescaler = TIM_ICPSC_DIV1;
  sConfigIC.ICFilter = 0;
  if (HAL_TIM_IC_ConfigChannel(&htim2, &sConfigIC, TIM_CHANNEL_1) != HAL_OK)
  {
    Error_Handler();
  }

}

static void MX_UART7_Init(void)
{

  huart7.Instance = UART7;
  huart7.Init.BaudRate = 115200;
  huart7.Init.WordLength = UART_WORDLENGTH_8B;
  huart7.Init.StopBits = UART_STOPBITS_1;
  huart7.Init.Parity = UART_PARITY_NONE;
  huart7.Init.Mode = UART_MODE_TX_RX;
  huart7.Init.HwFlowCtl = UART_HWCONTROL_NONE;
  huart7.Init.OverSampling = UART_OVERSAMPLING_16;
  huart7.Init.OneBitSampling = UART_ONE_BIT_SAMPLE_DISABLE;
  huart7.AdvancedInit.AdvFeatureInit = UART_ADVFEATURE_NO_INIT;
  if (HAL_UART_Init(&huart7) != HAL_OK)
  {
    Error_Handler();
  }

}

static void MX_USART1_UART_Init(void)
{

  huart1.Instance = USART1;
  huart1.Init.BaudRate = 115200;
  huart1.Init.WordLength = UART_WORDLENGTH_8B;
  huart1.Init.StopBits = UART_STOPBITS_1;
  huart1.Init.Parity = UART_PARITY_NONE;
  huart1.Init.Mode = UART_MODE_TX_RX;
  huart1.Init.HwFlowCtl = UART_HWCONTROL_NONE;
  huart1.Init.OverSampling = UART_OVERSAMPLING_16;
  huart1.Init.OneBitSampling = UART_ONE_BIT_SAMPLE_DISABLE;
  huart1.AdvancedInit.AdvFeatureInit = UART_ADVFEATURE_NO_INIT;
  if (HAL_UART_Init(&huart1) != HAL_OK)
  {
    Error_Handler();
  }

}

static void MX_USART6_UART_Init(void)
{

  huart6.Instance = USART6;
  huart6.Init.BaudRate = 115200;
  huart6.Init.WordLength = UART_WORDLENGTH_8B;
  huart6.Init.StopBits = UART_STOPBITS_1;
  huart6.Init.Parity = UART_PARITY_NONE;
  huart6.Init.Mode = UART_MODE_TX_RX;
  huart6.Init.HwFlowCtl = UART_HWCONTROL_NONE;
  huart6.Init.OverSampling = UART_OVERSAMPLING_16;
  huart6.Init.OneBitSampling = UART_ONE_BIT_SAMPLE_DISABLE;
  huart6.AdvancedInit.AdvFeatureInit = UART_ADVFEATURE_NO_INIT;
  if (HAL_UART_Init(&huart6) != HAL_OK)
  {
    Error_Handler();
  }

}

static void MX_USB_OTG_FS_PCD_Init(void)
{

  hpcd_USB_OTG_FS.Instance = USB_OTG_FS;
  hpcd_USB_OTG_FS.Init.dev_endpoints = 6;
  hpcd_USB_OTG_FS.Init.speed = PCD_SPEED_FULL;
  hpcd_USB_OTG_FS.Init.dma_enable = DISABLE;
  hpcd_USB_OTG_FS.Init.phy_itface = PCD_PHY_EMBEDDED;
  hpcd_USB_OTG_FS.Init.Sof_enable = DISABLE;
  hpcd_USB_OTG_FS.Init.low_power_enable = DISABLE;
  hpcd_USB_OTG_FS.Init.lpm_enable = DISABLE;
  hpcd_USB_OTG_FS.Init.vbus_sensing_enable = DISABLE;
  hpcd_USB_OTG_FS.Init.use_dedicated_ep1 = DISABLE;
  if (HAL_PCD_Init(&hpcd_USB_OTG_FS) != HAL_OK)
  {
    Error_Handler();
  }

}

static void MX_DMA_Init(void)
{

  /* DMA controller clock enable */
  __HAL_RCC_DMA2_CLK_ENABLE();
  __HAL_RCC_DMA1_CLK_ENABLE();

  /* DMA interrupt init */
  /* DMA1_Stream1_IRQn interrupt configuration */
  HAL_NVIC_SetPriority(DMA1_Stream1_IRQn, 5, 0);
  HAL_NVIC_EnableIRQ(DMA1_Stream1_IRQn);
  /* DMA1_Stream3_IRQn interrupt configuration */
  HAL_NVIC_SetPriority(DMA1_Stream3_IRQn, 5, 0);
  HAL_NVIC_EnableIRQ(DMA1_Stream3_IRQn);
  /* DMA2_Stream1_IRQn interrupt configuration */
  HAL_NVIC_SetPriority(DMA2_Stream1_IRQn, 5, 0);
  HAL_NVIC_EnableIRQ(DMA2_Stream1_IRQn);
  /* DMA2_Stream2_IRQn interrupt configuration */
  HAL_NVIC_SetPriority(DMA2_Stream2_IRQn, 5, 0);
  HAL_NVIC_EnableIRQ(DMA2_Stream2_IRQn);
  /* DMA2_Stream6_IRQn interrupt configuration */
  HAL_NVIC_SetPriority(DMA2_Stream6_IRQn, 5, 0);
  HAL_NVIC_EnableIRQ(DMA2_Stream6_IRQn);
  /* DMA2_Stream7_IRQn interrupt configuration */
  HAL_NVIC_SetPriority(DMA2_Stream7_IRQn, 5, 0);
  HAL_NVIC_EnableIRQ(DMA2_Stream7_IRQn);

}

/* FMC initialization function */
static void MX_FMC_Init(void)
{

  FMC_SDRAM_TimingTypeDef SdramTiming = {0};

  /** Perform the SDRAM1 memory initialization sequence
  */
  hsdram1.Instance = FMC_SDRAM_DEVICE;
  /* hsdram1.Init */
  hsdram1.Init.SDBank = FMC_SDRAM_BANK1;
  hsdram1.Init.ColumnBitsNumber = FMC_SDRAM_COLUMN_BITS_NUM_8;
  hsdram1.Init.RowBitsNumber = FMC_SDRAM_ROW_BITS_NUM_12;
  hsdram1.Init.MemoryDataWidth = FMC_SDRAM_MEM_BUS_WIDTH_16;
  hsdram1.Init.InternalBankNumber = FMC_SDRAM_INTERN_BANKS_NUM_4;
  hsdram1.Init.CASLatency = FMC_SDRAM_CAS_LATENCY_3;
  hsdram1.Init.WriteProtection = FMC_SDRAM_WRITE_PROTECTION_DISABLE;
  hsdram1.Init.SDClockPeriod = FMC_SDRAM_CLOCK_PERIOD_2;
  hsdram1.Init.ReadBurst = FMC_SDRAM_RBURST_ENABLE;
  hsdram1.Init.ReadPipeDelay = FMC_SDRAM_RPIPE_DELAY_0;
  /* SdramTiming */
  SdramTiming.LoadToActiveDelay = 2;
  SdramTiming.ExitSelfRefreshDelay = 7;
  SdramTiming.SelfRefreshTime = 4;
  SdramTiming.RowCycleDelay = 7;
  SdramTiming.WriteRecoveryTime = 3;
  SdramTiming.RPDelay = 2;
  SdramTiming.RCDDelay = 2;

  if (HAL_SDRAM_Init(&hsdram1, &SdramTiming) != HAL_OK)
  {
    Error_Handler( );
  }

}

static void MX_GPIO_Init(void)
{
  GPIO_InitTypeDef GPIO_InitStruct = {0};

  /* GPIO Ports Clock Enable */
  __HAL_RCC_GPIOE_CLK_ENABLE();
  __HAL_RCC_GPIOG_CLK_ENABLE();
  __HAL_RCC_GPIOB_CLK_ENABLE();
  __HAL_RCC_GPIOC_CLK_ENABLE();
  __HAL_RCC_GPIOA_CLK_ENABLE();
  __HAL_RCC_GPIOD_CLK_ENABLE();
  __HAL_RCC_GPIOI_CLK_ENABLE();
  __HAL_RCC_GPIOF_CLK_ENABLE();
  __HAL_RCC_GPIOH_CLK_ENABLE();

  /*Configure GPIO pin Output Level */
  HAL_GPIO_WritePin(EXT_RST_GPIO_Port, EXT_RST_Pin, GPIO_PIN_RESET);

  /*Configure GPIO pins : SDMMC_CK_Pin SDMMC_D3_Pin SDMMC_D2_Pin PC9
                           PC8 */
  GPIO_InitStruct.Pin = SDMMC_CK_Pin|SDMMC_D3_Pin|SDMMC_D2_Pin|GPIO_PIN_9
                          |GPIO_PIN_8;
  GPIO_InitStruct.Mode = GPIO_MODE_AF_PP;
  GPIO_InitStruct.Pull = GPIO_NOPULL;
  GPIO_InitStruct.Speed = GPIO_SPEED_FREQ_VERY_HIGH;
  GPIO_InitStruct.Alternate = GPIO_AF12_SDMMC1;
  HAL_GPIO_Init(GPIOC, &GPIO_InitStruct);

  /*Configure GPIO pin : SDMMC_CMD_Pin */
  GPIO_InitStruct.Pin = SDMMC_CMD_Pin;
  GPIO_InitStruct.Mode = GPIO_MODE_AF_PP;
  GPIO_InitStruct.Pull = GPIO_NOPULL;
  GPIO_InitStruct.Speed = GPIO_SPEED_FREQ_VERY_HIGH;
  GPIO_InitStruct.Alternate = GPIO_AF12_SDMMC1;
  HAL_GPIO_Init(SDMMC_CMD_GPIO_Port, &GPIO_InitStruct);

  /*Configure GPIO pins : TP3_Pin NC2_Pin */
  GPIO_InitStruct.Pin = TP3_Pin|NC2_Pin;
  GPIO_InitStruct.Mode = GPIO_MODE_INPUT;
  GPIO_InitStruct.Pull = GPIO_NOPULL;
  HAL_GPIO_Init(GPIOH, &GPIO_InitStruct);

  /*Configure GPIO pin : EXT_RST_Pin */
  GPIO_InitStruct.Pin = EXT_RST_Pin;
  GPIO_InitStruct.Mode = GPIO_MODE_OUTPUT_PP;
  GPIO_InitStruct.Pull = GPIO_NOPULL;
  GPIO_InitStruct.Speed = GPIO_SPEED_FREQ_LOW;
  HAL_GPIO_Init(EXT_RST_GPIO_Port, &GPIO_InitStruct);

  /*Configure GPIO pin : RMII_RXER_Pin */
  GPIO_InitStruct.Pin = RMII_RXER_Pin;
  GPIO_InitStruct.Mode = GPIO_MODE_INPUT;
  GPIO_InitStruct.Pull = GPIO_NOPULL;
  HAL_GPIO_Init(RMII_RXER_GPIO_Port, &GPIO_InitStruct);

}

/* USER CODE BEGIN 4 */
void vApplicationMallocFailedHook( void )
{
    printf( "Allocation failed.\r\n" );
}
/**
  * @brief  Retargets the C library printf function to the USART.
  */
int _write(int fd, char * ptr, int len)
{
	HAL_UART_Transmit(&huart1, (uint8_t *)ptr, len, HAL_MAX_DELAY);
	return len;
}

void pcNmeaRx_thread(void *argument)
{

	struct ExtrrState extrrState =
	{
		.startFound = false,
		.lastSrcSymbol = 0x00
	};

	/* Infinite loop */
	for(;;)
	{
		uint8_t rxBuf[UART_RX_CHUNK + 1] = {}; //1 protection byte
		if(HAL_UART_Receive_DMA(pcNmeaUart, rxBuf, UART_RX_CHUNK)!= HAL_OK)
		{
			printf("Reception error.\r\n");
		}
		/* Try to obtain the RX semaphore from DMA IRQ */
		osStatus_t semaStatus = osSemaphoreAcquire(pcNmeaRx_semaHandle , \
				UART_RX_TIMEOUT_MS/portTICK_PERIOD_MS);
		switch(semaStatus)
		{
			case osErrorTimeout :
			{
				HAL_UART_AbortReceive_IT(pcNmeaRx_semaHandle);
				//get data from buffer
				int rxBufIdx = 0;
				for( ; rxBuf[rxBufIdx] != 0x00; rxBufIdx++)
				{}
				if(rxBufIdx) //if data in buffer pass it to the parser
				{
					nmeaMsgExtractor(rxBuf, rxBufIdx + 1 /* from idx to amnt */,
						&pcNmeaMsgList,	&extrrState);
				}
				break;
			} //end case timeout
			case osOK :
			{
				nmeaMsgExtractor(rxBuf, UART_RX_CHUNK /* from idx to amnt */,
					&pcNmeaMsgList,	&extrrState);
				break;
			} //end case ok
			default :
			{
				printf("Unhandled error.\r\n");
				break;
			}
		} //end switch sema status
		checkProtection(pcNmeaMsgList);
	} //end for
}

#define UART_MAX_DELAY_MS	1000
#define UART_RX_BUF_SIZE    64
void gpsNmeaRx_thread(void *argument)
{
	/* Initialization */
	uint32_t semaAcqAtmptCnt = 0;

	uint32_t rxBufIdx = 0;
	uint32_t rxBufSize = UART_RX_BUF_SIZE;
	uint8_t rxBuf[rxBufSize + 1]; //1 protection byte
	rxBuf[rxBufSize] = MEM_PROT_SYMBOL;

	struct ExtrrState extrrState =
	{
		.startFound = false,
		.lastSrcSymbol = 0x00
	};

	/* Ignite transmission cycle */
reignite:
	debug("Ignition.\r\n");
	semaAcqAtmptCnt = 0;
	rxBufIdx = 0;
	memset(rxBuf, 0x00, UART_RX_BUF_SIZE); //clear
	HAL_UART_Receive_DMA(gpsNmeaUart, &rxBuf[0], rxBufSize);

	/* Infinite loop */
	for(;;)
	{
		/* Try to obtain the RX semaphore from DMA IRQ */
		osStatus_t semaStatus = osSemaphoreAcquire(gpsNmeaRx_semaHandle , \
				UART_RX_TIMEOUT_MS/portTICK_PERIOD_MS);
		switch(semaStatus)
		{
			case osErrorTimeout : //get what you can at the moment
			{
				semaAcqAtmptCnt++;
				if(semaAcqAtmptCnt == UART_MAX_DELAY_MS/UART_RX_TIMEOUT_MS)
				{
					goto reignite;
				}

				uint32_t avlblData = 0;
				uint32_t prevIdx = rxBufIdx;
				//define how much can be read from buffer
				for( ; (rxBuf[rxBufIdx] != 0x00) && \
					(rxBufIdx < rxBufSize);
						rxBufIdx++) //replace 'rxBufIdx' to the new terminator
				{
					avlblData++;
				}
				if(avlblData) //if data is in buffer, pass it to the parser
				{
					nmeaMsgExtractor(&rxBuf[prevIdx], avlblData /* from idx to amnt */,
						&gpsNmeaMsgList, &extrrState);
				}
				break;
			} //end case timeout
			case osOK : //semaphore acquired
			{
				nmeaMsgExtractor(&rxBuf[rxBufIdx], \
						rxBufSize - rxBufIdx, \
							&gpsNmeaMsgList, &extrrState);
				//next cycle
				rxBufIdx = 0;
				memset(rxBuf, 0x00, rxBufSize); //clear
				semaAcqAtmptCnt = 0;
				HAL_UART_Receive_DMA(gpsNmeaUart, rxBuf, rxBufSize);
				break;
			} //end case ok
			default :
			{
				debug("Unhandled error.\r\n");
				break;
			}
		} //end switch sema status
		checkProtection(gpsNmeaMsgList);
		assert( (rxBuf[rxBufSize] == MEM_PROT_SYMBOL) && \
						"RX buffer overflow");
	} //end for
}

/* USER CODE END 4 */

void StartDefaultTask(void *argument)
{
  /* init code for USB_DEVICE */
  MX_USB_DEVICE_Init();
  for(;;)
  {
    osDelay(1);
  }
}

 /**
  * @brief  Period elapsed callback in non blocking mode
  * @note   This function is called  when TIM6 interrupt took place, inside
  * HAL_TIM_IRQHandler(). It makes a direct call to HAL_IncTick() to increment
  * a global variable "uwTick" used as application time base.
  * @param  htim : TIM handle
  * @retval None
  */
void HAL_TIM_PeriodElapsedCallback(TIM_HandleTypeDef *htim)
{
  if (htim->Instance == TIM6) {
    HAL_IncTick();
  }
}

void Error_Handler(void)
{
}

/************************ (C) COPYRIGHT STMicroelectronics *****END OF FILE****/

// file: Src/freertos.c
/* USER CODE BEGIN Header */
/**
  ******************************************************************************
  * File Name          : freertos.c
  * Description        : Code for freertos applications
  ******************************************************************************
  * @attention
  *
  * <h2><center>&copy; Copyright (c) 2020 STMicroelectronics.
  * All rights reserved.</center></h2>
  *
  * This software component is licensed by ST under Ultimate Liberty license
  * SLA0044, the "License"; You may not use this file except in compliance with
  * the License. You may obtain a copy of the License at:
  *                             www.st.com/SLA0044
  *
  ******************************************************************************
  */
/* USER CODE END Header */

#include "FreeRTOS.h"
#include "task.h"
#include "main.h"

/* Hook prototypes */
void vApplicationIdleHook(void);
void vApplicationStackOverflowHook(xTaskHandle xTask, signed char *pcTaskName);
void vApplicationMallocFailedHook(void);

/* USER CODE BEGIN 2 */
__weak void vApplicationIdleHook( void )
{
   /* vApplicationIdleHook() will only be called if configUSE_IDLE_HOOK is set
   to 1 in FreeRTOSConfig.h. It will be called on each iteration of the idle
   task. It is essential that code added to this hook function never attempts
   to block in any way (for example, call xQueueReceive() with a block time
   specified, or call vTaskDelay()). If the application makes use of the
   vTaskDelete() API function (as this demo application does) then it is also
   important that vApplicationIdleHook() is permitted to return to its calling
   function, because it is the responsibility of the idle task to clean up
   memory allocated by the kernel to any task that has since been deleted. */
}
/* USER CODE END 2 */

/* USER CODE BEGIN 4 */
__weak void vApplicationStackOverflowHook(xTaskHandle xTask, signed char *pcTaskName)
{
   /* Run time stack overflow checking is performed if
   configCHECK_FOR_STACK_OVERFLOW is defined to 1 or 2. This hook function is
   called if a stack overflow is detected. */
}
/* USER CODE END 4 */

/* USER CODE BEGIN 5 */
__weak void vApplicationMallocFailedHook(void)
{
   /* vApplicationMallocFailedHook() will only be called if
   configUSE_MALLOC_FAILED_HOOK is set to 1 in FreeRTOSConfig.h. It is a hook
   function that will get called if a call to pvPortMalloc() fails.
   pvPortMalloc() is called internally by the kernel whenever a task, queue,
   timer or semaphore is created. It is also called by various parts of the
   demo application. If heap_1.c or heap_2.c are used, then the size of the
   heap available to pvPortMalloc() is defined by configTOTAL_HEAP_SIZE in
   FreeRTOSConfig.h, and the xPortGetFreeHeapSize() API function can be used
   to query the size of free heap space that remains (although it does not
   provide information on how the remaining heap might be fragmented). */
}
/* USER CODE END 5 */

/************************ (C) COPYRIGHT STMicroelectronics *****END OF FILE****/
